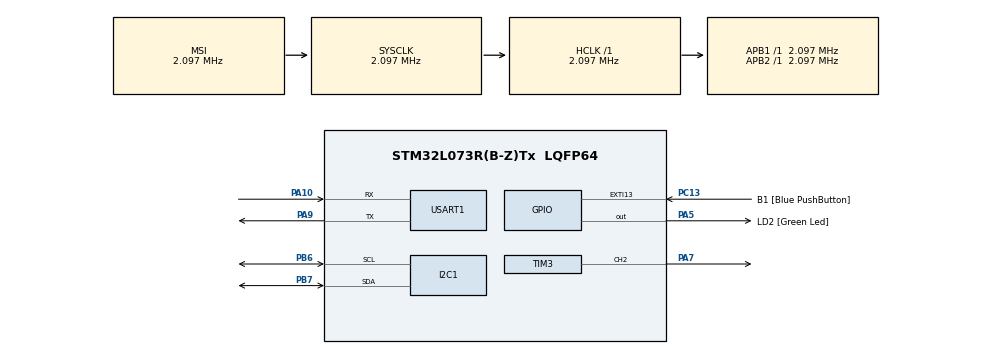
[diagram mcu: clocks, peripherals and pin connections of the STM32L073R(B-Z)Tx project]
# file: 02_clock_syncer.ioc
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I2C1.Timing=0x00000608
LPTIM1.ClockPrescaler=LPTIM_PRESCALER_DIV128
Mcu.Family=STM32L0
Mcu.Name=STM32L073R(B-Z)Tx
Mcu.Package=LQFP64
NVIC.LPTIM1_IRQn=true\:0\:0\:false\:false\:true\:true\:true\:true
NVIC.USART1_IRQn=true\:0\:0\:false\:false\:true\:true\:true\:true
PA10.Mode=Asynchronous
PA10.Signal=USART1_RX
PA13.GPIO_Label=TMS
PA13.Mode=Serial_Wire
PA13.Signal=SYS_SWDIO
PA14.GPIO_Label=TCK
PA14.Mode=Serial_Wire
PA14.Signal=SYS_SWCLK
PA2.GPIO_Label=USART_TX
PA2.Signal=USART2_TX
PA3.GPIO_Label=USART_RX
PA3.Signal=USART2_RX
PA5.GPIO_Label=LD2 [Green Led]
PA5.Signal=GPIO_Output
PA7.Signal=S_TIM3_CH2
PA9.Mode=Asynchronous
PA9.Signal=USART1_TX
PB6.Mode=I2C
PB6.Signal=I2C1_SCL
PB7.Mode=I2C
PB7.Signal=I2C1_SDA
PC13.GPIO_Label=B1 [Blue PushButton]
PC13.GPIO_ModeDefaultEXTI=GPIO_MODE_IT_FALLING
PC13.Signal=GPXTI13
PC14-OSC32_IN.Mode=LSE-External-Oscillator
PC14-OSC32_IN.Signal=RCC_OSC32_IN
PC15-OSC32_OUT.Mode=LSE-External-Oscillator
PC15-OSC32_OUT.Signal=RCC_OSC32_OUT
PH0-OSC_IN.GPIO_Label=MCO
PH0-OSC_IN.Mode=HSE-External-Clock-Source
PH0-OSC_IN.Signal=RCC_OSC_IN
ProjectManager.HeapSize=0x200
ProjectManager.StackSize=0x400
ProjectManager.TargetToolchain=STM32CubeIDE
RCC.AHBFreq_Value=2097000
RCC.APB1Freq_Value=2097000
RCC.APB1TimFreq_Value=2097000
RCC.APB2Freq_Value=2097000
RCC.APB2TimFreq_Value=2097000
RCC.HSE_VALUE=8000000
RCC.HSI16_VALUE=16000000
RCC.HSI48_VALUE=48000000
RCC.HSI_VALUE=16000000
RCC.LptimClockSelection=RCC_LPTIM1CLKSOURCE_LSE
RCC.MSI_VALUE=2097000
RCC.RTCClockSelection=RCC_RTCCLKSOURCE_LSE
RCC.RTCClockSelectionVirtual=RCC_RTCCLKSOURCE_LSE
RCC.SYSCLKFreq_VALUE=2097000
RCC.VCOOutputFreq_Value=48000000
SH.S_TIM3_CH2.0=TIM3_CH2,PWM Generation2 CH2
TIM2.Prescaler=1
TIM3.Channel-PWM\ Generation2\ CH2=TIM_CHANNEL_2
TIM3.Period=999
TIM3.Prescaler=31
TIM3.Pulse-PWM\ Generation2\ CH2=499
USART1.VirtualMode-Asynchronous=VM_ASYNC
VP_LPTIM1_VS_LPTIM_counterModeInternalClock.Mode=Counts__internal_clock_event_00
VP_RTC_VS_RTC_Activate.Mode=RTC_Enabled
VP_TIM2_VS_ClockSourceINT.Mode=Internal
VP_TIM3_VS_ClockSourceINT.Mode=Internal
board=NUCLEO-L073RZ

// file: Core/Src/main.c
/* USER CODE BEGIN Header */
/**
  ******************************************************************************
  * @file           : main.c
  * @brief          : Main program body
  ******************************************************************************
  * @attention
  *
  * Copyright (c) 2025 STMicroelectronics.
  * All rights reserved.
  *
  * This software is licensed under terms that can be found in the LICENSE file
  * in the root directory of this software component.
  * If no LICENSE file comes with this software, it is provided AS-IS.
  *
  ******************************************************************************
  */
/* USER CODE END Header */
#include "main.h"

/* USER CODE BEGIN Includes */
#include "rtc_driver_api.h"
#include "event_loop.h"
/* USER CODE END Includes */

I2C_HandleTypeDef hi2c1;

RTC_HandleTypeDef hrtc;

TIM_HandleTypeDef htim2;
TIM_HandleTypeDef htim3;

UART_HandleTypeDef huart1;

void SystemClock_Config(void);
static void MX_GPIO_Init(void);
static void MX_USART1_UART_Init(void);
static void MX_I2C1_Init(void);
static void MX_LPTIM1_Init(void);
static void MX_RTC_Init(void);
static void MX_TIM2_Init(void);
static void MX_TIM3_Init(void);

int main(void)
{

  /* MCU Configuration--------------------------------------------------------*/

  /* Reset of all peripherals, Initializes the Flash interface and the Systick. */
  HAL_Init();

  /* Configure the system clock */
  SystemClock_Config();

  /* Initialize all configured peripherals */
  MX_GPIO_Init();
  MX_USART1_UART_Init();
  MX_I2C1_Init();
  MX_LPTIM1_Init();
  MX_RTC_Init();
  MX_TIM2_Init();
  MX_TIM3_Init();
  /* USER CODE BEGIN 2 */
  rtc_protocol_main();
  hcsr04_init(&hcsr04_config);
  hw512_init(&buzzer_config);
  /* USER CODE END 2 */

  /* Infinite loop */
  /* USER CODE BEGIN WHILE */
  while (1)
  {
	  if(event_flags){
		  process_events();
	  }
    /* USER CODE END WHILE */

  }
}

void SystemClock_Config(void)
{
  RCC_OscInitTypeDef RCC_OscInitStruct = {0};
  RCC_ClkInitTypeDef RCC_ClkInitStruct = {0};
  RCC_PeriphCLKInitTypeDef PeriphClkInit = {0};

  /** Configure the main internal regulator output voltage
  */
  __HAL_PWR_VOLTAGESCALING_CONFIG(PWR_REGULATOR_VOLTAGE_SCALE1);

  /** Configure LSE Drive Capability
  */
  HAL_PWR_EnableBkUpAccess();
  __HAL_RCC_LSEDRIVE_CONFIG(RCC_LSEDRIVE_LOW);

  /** Initializes the RCC Oscillators according to the specified parameters
  * in the RCC_OscInitTypeDef structure.
  */
  RCC_OscInitStruct.OscillatorType = RCC_OSCILLATORTYPE_LSE|RCC_OSCILLATORTYPE_MSI;
  RCC_OscInitStruct.LSEState = RCC_LSE_ON;
  RCC_OscInitStruct.MSIState = RCC_MSI_ON;
  RCC_OscInitStruct.MSICalibrationValue = 0;
  RCC_OscInitStruct.MSIClockRange = RCC_MSIRANGE_5;
  RCC_OscInitStruct.PLL.PLLState = RCC_PLL_NONE;
  if (HAL_RCC_OscConfig(&RCC_OscInitStruct) != HAL_OK)
  {
    Error_Handler();
  }

  /** Initializes the CPU, AHB and APB buses clocks
  */
  RCC_ClkInitStruct.ClockType = RCC_CLOCKTYPE_HCLK|RCC_CLOCKTYPE_SYSCLK
                              |RCC_CLOCKTYPE_PCLK1|RCC_CLOCKTYPE_PCLK2;
  RCC_ClkInitStruct.SYSCLKSource = RCC_SYSCLKSOURCE_MSI;
  RCC_ClkInitStruct.AHBCLKDivider = RCC_SYSCLK_DIV1;
  RCC_ClkInitStruct.APB1CLKDivider = RCC_HCLK_DIV1;
  RCC_ClkInitStruct.APB2CLKDivider = RCC_HCLK_DIV1;

  if (HAL_RCC_ClockConfig(&RCC_ClkInitStruct, FLASH_LATENCY_0) != HAL_OK)
  {
    Error_Handler();
  }
  PeriphClkInit.PeriphClockSelection = RCC_PERIPHCLK_USART1|RCC_PERIPHCLK_I2C1
                              |RCC_PERIPHCLK_RTC|RCC_PERIPHCLK_LPTIM1;
  PeriphClkInit.Usart1ClockSelection = RCC_USART1CLKSOURCE_PCLK2;
  PeriphClkInit.I2c1ClockSelection = RCC_I2C1CLKSOURCE_PCLK1;
  PeriphClkInit.RTCClockSelection = RCC_RTCCLKSOURCE_LSE;
  PeriphClkInit.LptimClockSelection = RCC_LPTIM1CLKSOURCE_LSE;

  if (HAL_RCCEx_PeriphCLKConfig(&PeriphClkInit) != HAL_OK)
  {
    Error_Handler();
  }
}

static void MX_I2C1_Init(void)
{

  hi2c1.Instance = I2C1;
  hi2c1.Init.Timing = 0x00000608;
  hi2c1.Init.OwnAddress1 = 0;
  hi2c1.Init.AddressingMode = I2C_ADDRESSINGMODE_7BIT;
  hi2c1.Init.DualAddressMode = I2C_DUALADDRESS_DISABLE;
  hi2c1.Init.OwnAddress2 = 0;
  hi2c1.Init.OwnAddress2Masks = I2C_OA2_NOMASK;
  hi2c1.Init.GeneralCallMode = I2C_GENERALCALL_DISABLE;
  hi2c1.Init.NoStretchMode = I2C_NOSTRETCH_DISABLE;
  if (HAL_I2C_Init(&hi2c1) != HAL_OK)
  {
    Error_Handler();
  }

  /** Configure Analogue filter
  */
  if (HAL_I2CEx_ConfigAnalogFilter(&hi2c1, I2C_ANALOGFILTER_ENABLE) != HAL_OK)
  {
    Error_Handler();
  }

  /** Configure Digital filter
  */
  if (HAL_I2CEx_ConfigDigitalFilter(&hi2c1, 0) != HAL_OK)
  {
    Error_Handler();
  }

}

static void MX_LPTIM1_Init(void)
{

  /* Peripheral clock enable */
  LL_APB1_GRP1_EnableClock(LL_APB1_GRP1_PERIPH_LPTIM1);

  /* LPTIM1 interrupt Init */
  NVIC_SetPriority(LPTIM1_IRQn, 0);
  NVIC_EnableIRQ(LPTIM1_IRQn);

  /* USER CODE BEGIN LPTIM1_Init 1 */
  LL_LPTIM_Enable(LPTIM1);

  /* USER CODE END LPTIM1_Init 1 */
  LL_LPTIM_SetClockSource(LPTIM1, LL_LPTIM_CLK_SOURCE_INTERNAL);
  LL_LPTIM_SetPrescaler(LPTIM1, LL_LPTIM_PRESCALER_DIV128);
  LL_LPTIM_SetPolarity(LPTIM1, LL_LPTIM_OUTPUT_POLARITY_REGULAR);
  LL_LPTIM_SetUpdateMode(LPTIM1, LL_LPTIM_UPDATE_MODE_IMMEDIATE);
  LL_LPTIM_SetCounterMode(LPTIM1, LL_LPTIM_COUNTER_MODE_INTERNAL);
  LL_LPTIM_TrigSw(LPTIM1);
  /* USER CODE BEGIN LPTIM1_Init 2 */
  LL_LPTIM_TrigSw(LPTIM1);
  LL_LPTIM_SetAutoReload(LPTIM1, 63);  // ARR = counts - 1
  LL_LPTIM_EnableIT_ARRM(LPTIM1);
  LL_LPTIM_StartCounter(LPTIM1, LL_LPTIM_OPERATING_MODE_CONTINUOUS);
  /* USER CODE END LPTIM1_Init 2 */

}

static void MX_RTC_Init(void)
{

  /** Initialize RTC Only
  */
  hrtc.Instance = RTC;
  hrtc.Init.HourFormat = RTC_HOURFORMAT_24;
  hrtc.Init.AsynchPrediv = 127;
  hrtc.Init.SynchPrediv = 255;
  hrtc.Init.OutPut = RTC_OUTPUT_DISABLE;
  hrtc.Init.OutPutRemap = RTC_OUTPUT_REMAP_NONE;
  hrtc.Init.OutPutPolarity = RTC_OUTPUT_POLARITY_HIGH;
  hrtc.Init.OutPutType = RTC_OUTPUT_TYPE_OPENDRAIN;
  if (HAL_RTC_Init(&hrtc) != HAL_OK)
  {
    Error_Handler();
  }

}

static void MX_TIM2_Init(void)
{

  TIM_ClockConfigTypeDef sClockSourceConfig = {0};
  TIM_MasterConfigTypeDef sMasterConfig = {0};

  htim2.Instance = TIM2;
  htim2.Init.Prescaler = 1;
  htim2.Init.CounterMode = TIM_COUNTERMODE_UP;
  htim2.Init.Period = 65535;
  htim2.Init.ClockDivision = TIM_CLOCKDIVISION_DIV1;
  htim2.Init.AutoReloadPreload = TIM_AUTORELOAD_PRELOAD_DISABLE;
  if (HAL_TIM_Base_Init(&htim2) != HAL_OK)
  {
    Error_Handler();
  }
  sClockSourceConfig.ClockSource = TIM_CLOCKSOURCE_INTERNAL;
  if (HAL_TIM_ConfigClockSource(&htim2, &sClockSourceConfig) != HAL_OK)
  {
    Error_Handler();
  }
  sMasterConfig.MasterOutputTrigger = TIM_TRGO_RESET;
  sMasterConfig.MasterSlaveMode = TIM_MASTERSLAVEMODE_DISABLE;
  if (HAL_TIMEx_MasterConfigSynchronization(&htim2, &sMasterConfig) != HAL_OK)
  {
    Error_Handler();
  }

}

static void MX_TIM3_Init(void)
{

  TIM_ClockConfigTypeDef sClockSourceConfig = {0};
  TIM_MasterConfigTypeDef sMasterConfig = {0};
  TIM_OC_InitTypeDef sConfigOC = {0};

  htim3.Instance = TIM3;
  htim3.Init.Prescaler = 31;
  htim3.Init.CounterMode = TIM_COUNTERMODE_UP;
  htim3.Init.Period = 999;
  htim3.Init.ClockDivision = TIM_CLOCKDIVISION_DIV1;
  htim3.Init.AutoReloadPreload = TIM_AUTORELOAD_PRELOAD_DISABLE;
  if (HAL_TIM_Base_Init(&htim3) != HAL_OK)
  {
    Error_Handler();
  }
  sClockSourceConfig.ClockSource = TIM_CLOCKSOURCE_INTERNAL;
  if (HAL_TIM_ConfigClockSource(&htim3, &sClockSourceConfig) != HAL_OK)
  {
    Error_Handler();
  }
  if (HAL_TIM_PWM_Init(&htim3) != HAL_OK)
  {
    Error_Handler();
  }
  sMasterConfig.MasterOutputTrigger = TIM_TRGO_RESET;
  sMasterConfig.MasterSlaveMode = TIM_MASTERSLAVEMODE_DISABLE;
  if (HAL_TIMEx_MasterConfigSynchronization(&htim3, &sMasterConfig) != HAL_OK)
  {
    Error_Handler();
  }
  sConfigOC.OCMode = TIM_OCMODE_PWM1;
  sConfigOC.Pulse = 499;
  sConfigOC.OCPolarity = TIM_OCPOLARITY_HIGH;
  sConfigOC.OCFastMode = TIM_OCFAST_DISABLE;
  if (HAL_TIM_PWM_ConfigChannel(&htim3, &sConfigOC, TIM_CHANNEL_2) != HAL_OK)
  {
    Error_Handler();
  }
  HAL_TIM_MspPostInit(&htim3);

}

static void MX_USART1_UART_Init(void)
{

  huart1.Instance = USART1;
  huart1.Init.BaudRate = 115200;
  huart1.Init.WordLength = UART_WORDLENGTH_8B;
  huart1.Init.StopBits = UART_STOPBITS_1;
  huart1.Init.Parity = UART_PARITY_NONE;
  huart1.Init.Mode = UART_MODE_TX_RX;
  huart1.Init.HwFlowCtl = UART_HWCONTROL_NONE;
  huart1.Init.OverSampling = UART_OVERSAMPLING_16;
  huart1.Init.OneBitSampling = UART_ONE_BIT_SAMPLE_DISABLE;
  huart1.AdvancedInit.AdvFeatureInit = UART_ADVFEATURE_NO_INIT;
  if (HAL_UART_Init(&huart1) != HAL_OK)
  {
    Error_Handler();
  }

}

static void MX_GPIO_Init(void)
{
  GPIO_InitTypeDef GPIO_InitStruct = {0};

  /* GPIO Ports Clock Enable */
  __HAL_RCC_GPIOC_CLK_ENABLE();
  __HAL_RCC_GPIOH_CLK_ENABLE();
  __HAL_RCC_GPIOA_CLK_ENABLE();
  __HAL_RCC_GPIOB_CLK_ENABLE();

  /*Configure GPIO pin Output Level */
  HAL_GPIO_WritePin(LD2_GPIO_Port, LD2_Pin, GPIO_PIN_RESET);

  /*Configure GPIO pin : B1_Pin */
  GPIO_InitStruct.Pin = B1_Pin;
  GPIO_InitStruct.Mode = GPIO_MODE_IT_FALLING;
  GPIO_InitStruct.Pull = GPIO_NOPULL;
  HAL_GPIO_Init(B1_GPIO_Port, &GPIO_InitStruct);

  /*Configure GPIO pins : USART_TX_Pin USART_RX_Pin */
  GPIO_InitStruct.Pin = USART_TX_Pin|USART_RX_Pin;
  GPIO_InitStruct.Mode = GPIO_MODE_AF_PP;
  GPIO_InitStruct.Pull = GPIO_NOPULL;
  GPIO_InitStruct.Speed = GPIO_SPEED_FREQ_VERY_HIGH;
  GPIO_InitStruct.Alternate = GPIO_AF4_USART2;
  HAL_GPIO_Init(GPIOA, &GPIO_InitStruct);

  /*Configure GPIO pin : LD2_Pin */
  GPIO_InitStruct.Pin = LD2_Pin;
  GPIO_InitStruct.Mode = GPIO_MODE_OUTPUT_PP;
  GPIO_InitStruct.Pull = GPIO_NOPULL;
  GPIO_InitStruct.Speed = GPIO_SPEED_FREQ_LOW;
  HAL_GPIO_Init(LD2_GPIO_Port, &GPIO_InitStruct);

}

void Error_Handler(void)
{
  __disable_irq();
  while (1)
  {
  }
}
